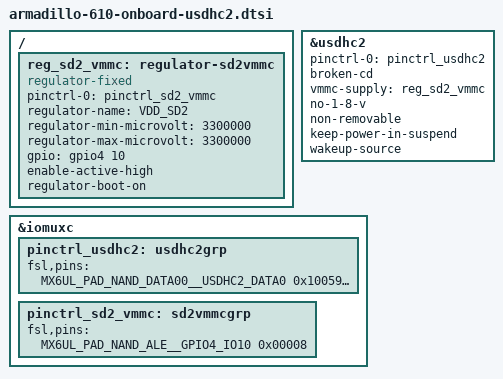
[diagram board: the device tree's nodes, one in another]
/*
 * Copyright (C) 2020 Atmark Techno, Inc. All Rights Reserved.
 *
 * SPDX-License-Identifier: (GPL-2.0 OR MIT)
 */

/ {
	reg_sd2_vmmc: regulator-sd2vmmc {
		pinctrl-names = "default";
		pinctrl-0 = <&pinctrl_sd2_vmmc>;
		compatible = "regulator-fixed";
		regulator-name = "VDD_SD2";
		regulator-min-microvolt = <3300000>;
		regulator-max-microvolt = <3300000>;
		gpio = <&gpio4 10 GPIO_ACTIVE_HIGH>;
		enable-active-high;
		regulator-boot-on;
	};
};

&usdhc2 {
	pinctrl-names = "default";
	pinctrl-0 = <&pinctrl_usdhc2>;
	broken-cd;
	vmmc-supply = <&reg_sd2_vmmc>;
	no-1-8-v;
	non-removable;
	keep-power-in-suspend;
	wakeup-source;
	status = "okay";
};

&iomuxc {
	pinctrl_usdhc2: usdhc2grp {
		fsl,pins = <
			MX6UL_PAD_NAND_DATA00__USDHC2_DATA0 0x10059
			MX6UL_PAD_NAND_DATA01__USDHC2_DATA1 0x10059
			MX6UL_PAD_NAND_DATA02__USDHC2_DATA2 0x10059
			MX6UL_PAD_NAND_DATA03__USDHC2_DATA3 0x10059
			MX6UL_PAD_NAND_RE_B__USDHC2_CLK     0x10069
			MX6UL_PAD_NAND_WE_B__USDHC2_CMD     0x10059
		>;
	};

	pinctrl_sd2_vmmc: sd2vmmcgrp {
		fsl,pins = <
			MX6UL_PAD_NAND_ALE__GPIO4_IO10  0x00008
		>;
	};
};
